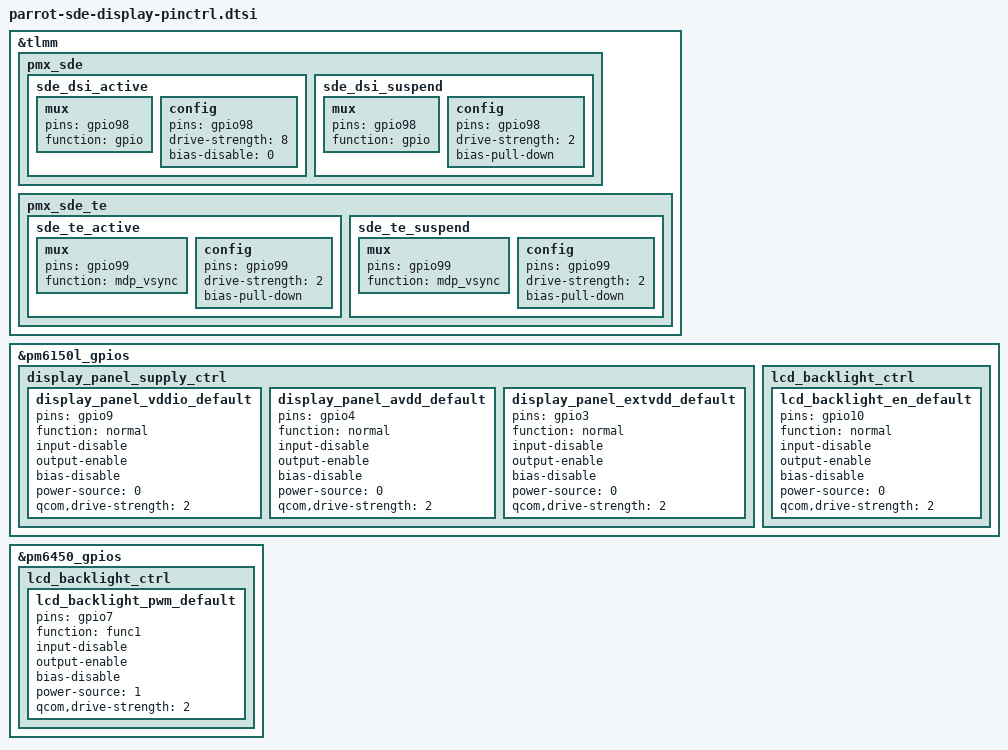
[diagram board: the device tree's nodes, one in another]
&tlmm {
	pmx_sde: pmx_sde {
		sde_dsi_active: sde_dsi_active {
			mux {
				pins = "gpio98";
				function = "gpio";
			};

			config {
				pins = "gpio98";
				drive-strength = <8>;   /* 8 mA */
				bias-disable = <0>;   /* no pull */
			};
		};

		sde_dsi_suspend: sde_dsi_suspend {
			mux {
				pins = "gpio98";
				function = "gpio";
			};

			config {
				pins = "gpio98";
				drive-strength = <2>;   /* 2 mA */
				bias-pull-down;         /* PULL DOWN */
			};
		};
	};

	pmx_sde_te: pmx_sde_te {
		sde_te_active: sde_te_active {
			mux {
				pins = "gpio99";
				function = "mdp_vsync";
			};

			config {
				pins = "gpio99";
				drive-strength = <2>;   /* 2 mA */
				bias-pull-down;         /* PULL DOWN */
			};
		};

		sde_te_suspend: sde_te_suspend {
			mux {
				pins = "gpio99";
				function = "mdp_vsync";
			};

			config {
				pins = "gpio99";
				drive-strength = <2>;   /* 2 mA */
				bias-pull-down;         /* PULL DOWN */
			};
		};
	};
};

&pm6150l_gpios {
	display_panel_supply_ctrl {
		display_panel_vddio_default: display_panel_vddio_default {
			pins = "gpio9";
			function = "normal";
			input-disable;
			output-enable;
			bias-disable;
			power-source = <0>;
			qcom,drive-strength = <2>;
		};

		display_panel_avdd_default: display_panel_avdd_default {
			pins = "gpio4";
			function = "normal";
			input-disable;
			output-enable;
			bias-disable;
			power-source = <0>;
			qcom,drive-strength = <2>;
		};

		display_panel_extvdd_default: display_panel_extvdd_default {
			pins = "gpio3";
			function = "normal";
			input-disable;
			output-enable;
			bias-disable;
			power-source = <0>;
			qcom,drive-strength = <2>;
		};
	};

	lcd_backlight_ctrl {
		lcd_backlight_en_default: lcd_backlight_en_default {
			pins = "gpio10";
			function = "normal";
			input-disable;
			output-enable;
			bias-disable;
			power-source = <0>;
			qcom,drive-strength = <2>;
		};
	};
};

&pm6450_gpios {
	lcd_backlight_ctrl {
		lcd_backlight_pwm_default: lcd_backlight_pwm_default {
			pins = "gpio7";
			function = "func1";
			input-disable;
			output-enable;
			bias-disable;
			power-source = <1>;       /* 1.8V */
			qcom,drive-strength = <2>;
		};
	};
};
